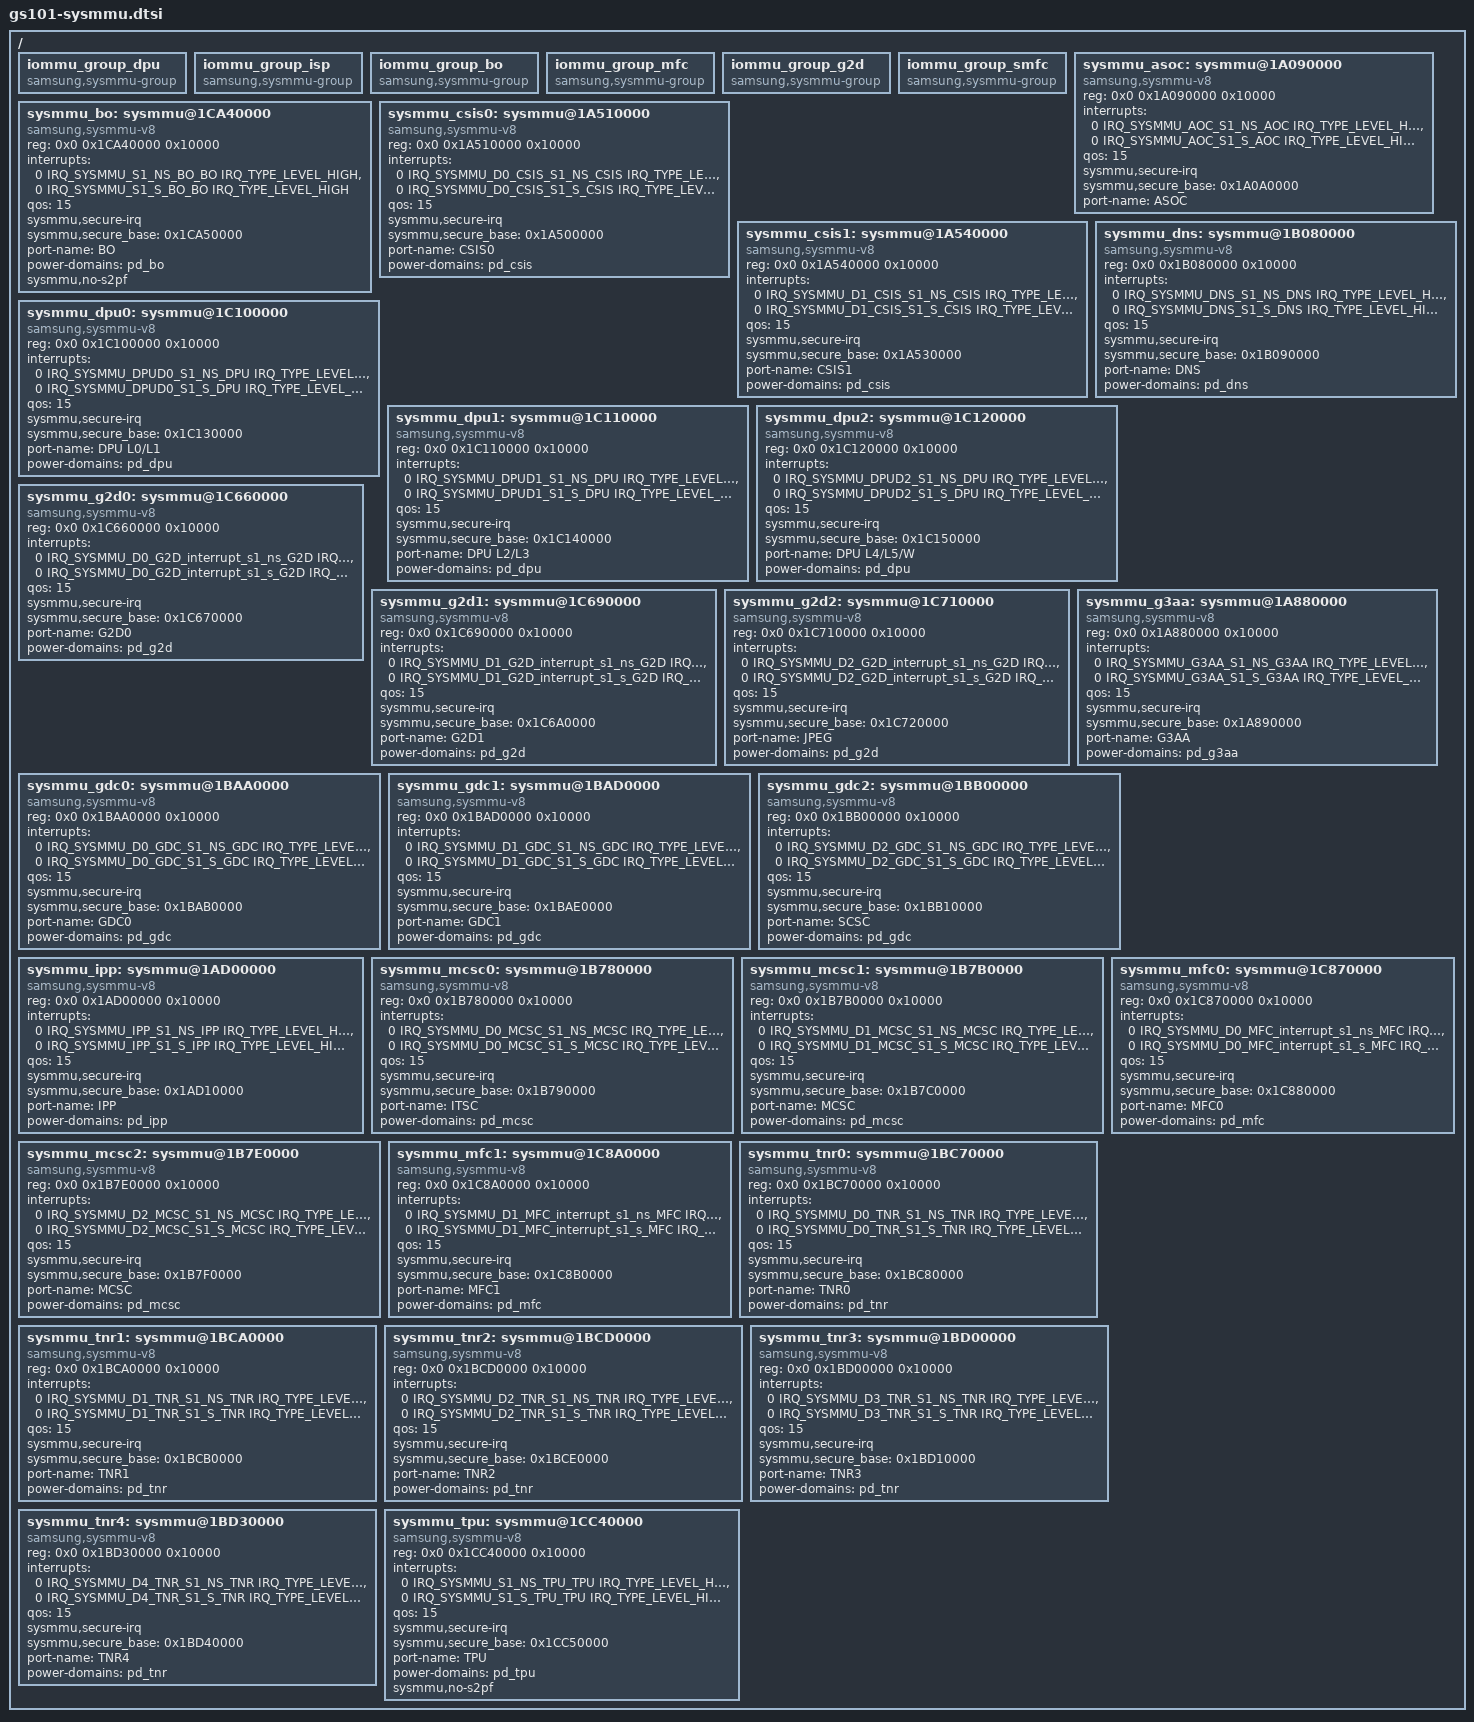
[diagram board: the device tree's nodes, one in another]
// SPDX-License-Identifier: GPL-2.0-only
/*
 * GS101 SoC System MMU
 *
 * Copyright 2019 Google LLC
 */

#include <dt-bindings/interrupt-controller/arm-gic.h>
#include <dt-bindings/interrupt-controller/gs101.h>
#include <dt-bindings/soc/samsung,sysmmu-v8.h>

/ {
	iommu_group_dpu: iommu_group_dpu {
		compatible = "samsung,sysmmu-group";
	};

	iommu_group_isp: iommu_group_isp {
		compatible = "samsung,sysmmu-group";
	};

	iommu_group_bo: iommu_group_bo {
		compatible = "samsung,sysmmu-group";
	};

	iommu_group_mfc: iommu_group_mfc {
		compatible = "samsung,sysmmu-group";
	};

	iommu_group_g2d: iommu_group_g2d {
		compatible = "samsung,sysmmu-group";
	};

	iommu_group_smfc: iommu_group_smfc {
		compatible = "samsung,sysmmu-group";
	};

	sysmmu_asoc: sysmmu@1A090000 {
		compatible = "samsung,sysmmu-v8";
		reg = <0x0 0x1A090000 0x10000>;
		interrupts = <0 IRQ_SYSMMU_AOC_S1_NS_AOC IRQ_TYPE_LEVEL_HIGH>,
			     <0 IRQ_SYSMMU_AOC_S1_S_AOC  IRQ_TYPE_LEVEL_HIGH>;
		qos = <15>;
		sysmmu,secure-irq;
		sysmmu,secure_base = <0x1A0A0000>;
		port-name = "ASOC";
		#iommu-cells = <0>;
	};

	sysmmu_bo: sysmmu@1CA40000 {
		compatible = "samsung,sysmmu-v8";
		reg = <0x0 0x1CA40000 0x10000>;
		interrupts = <0 IRQ_SYSMMU_S1_NS_BO_BO IRQ_TYPE_LEVEL_HIGH>,
			     <0 IRQ_SYSMMU_S1_S_BO_BO  IRQ_TYPE_LEVEL_HIGH>;
		qos = <15>;
		sysmmu,secure-irq;
		sysmmu,secure_base = <0x1CA50000>;
		port-name = "BO";
		#iommu-cells = <0>;
		power-domains = <&pd_bo>;
		sysmmu,no-s2pf;
	};

	sysmmu_csis0: sysmmu@1A510000 {
		compatible = "samsung,sysmmu-v8";
		reg = <0x0 0x1A510000 0x10000>;
		interrupts = <0 IRQ_SYSMMU_D0_CSIS_S1_NS_CSIS IRQ_TYPE_LEVEL_HIGH>,
			     <0 IRQ_SYSMMU_D0_CSIS_S1_S_CSIS  IRQ_TYPE_LEVEL_HIGH>;
		qos = <15>;
		sysmmu,secure-irq;
		sysmmu,secure_base = <0x1A500000>;
		port-name = "CSIS0";
		#iommu-cells = <0>;
		power-domains = <&pd_csis>;
	};

	sysmmu_csis1: sysmmu@1A540000 {
		compatible = "samsung,sysmmu-v8";
		reg = <0x0 0x1A540000 0x10000>;
		interrupts = <0 IRQ_SYSMMU_D1_CSIS_S1_NS_CSIS IRQ_TYPE_LEVEL_HIGH>,
			     <0 IRQ_SYSMMU_D1_CSIS_S1_S_CSIS  IRQ_TYPE_LEVEL_HIGH>;
		qos = <15>;
		sysmmu,secure-irq;
		sysmmu,secure_base = <0x1A530000>;
		port-name = "CSIS1";
		#iommu-cells = <0>;
		power-domains = <&pd_csis>;
	};

	sysmmu_dns: sysmmu@1B080000 {
		compatible = "samsung,sysmmu-v8";
		reg = <0x0 0x1B080000 0x10000>;
		interrupts = <0 IRQ_SYSMMU_DNS_S1_NS_DNS IRQ_TYPE_LEVEL_HIGH>,
			     <0 IRQ_SYSMMU_DNS_S1_S_DNS  IRQ_TYPE_LEVEL_HIGH>;
		qos = <15>;
		sysmmu,secure-irq;
		sysmmu,secure_base = <0x1B090000>;
		port-name = "DNS";
		#iommu-cells = <0>;
		power-domains = <&pd_dns>;
	};

	sysmmu_dpu0: sysmmu@1C100000 {
		compatible = "samsung,sysmmu-v8";
		reg = <0x0 0x1C100000 0x10000>;
		interrupts = <0 IRQ_SYSMMU_DPUD0_S1_NS_DPU IRQ_TYPE_LEVEL_HIGH>,
			     <0 IRQ_SYSMMU_DPUD0_S1_S_DPU  IRQ_TYPE_LEVEL_HIGH>;
		qos = <15>;
		sysmmu,secure-irq;
		sysmmu,secure_base = <0x1C130000>;
		port-name = "DPU L0/L1";
		#iommu-cells = <0>;
		power-domains = <&pd_dpu>;
	};

	sysmmu_dpu1: sysmmu@1C110000 {
		compatible = "samsung,sysmmu-v8";
		reg = <0x0 0x1C110000 0x10000>;
		interrupts = <0 IRQ_SYSMMU_DPUD1_S1_NS_DPU IRQ_TYPE_LEVEL_HIGH>,
			     <0 IRQ_SYSMMU_DPUD1_S1_S_DPU  IRQ_TYPE_LEVEL_HIGH>;
		qos = <15>;
		sysmmu,secure-irq;
		sysmmu,secure_base = <0x1C140000>;
		port-name = "DPU L2/L3";
		#iommu-cells = <0>;
		power-domains = <&pd_dpu>;
	};

	sysmmu_dpu2: sysmmu@1C120000 {
		compatible = "samsung,sysmmu-v8";
		reg = <0x0 0x1C120000 0x10000>;
		interrupts = <0 IRQ_SYSMMU_DPUD2_S1_NS_DPU IRQ_TYPE_LEVEL_HIGH>,
			     <0 IRQ_SYSMMU_DPUD2_S1_S_DPU  IRQ_TYPE_LEVEL_HIGH>;
		qos = <15>;
		sysmmu,secure-irq;
		sysmmu,secure_base = <0x1C150000>;
		port-name = "DPU L4/L5/W";
		#iommu-cells = <0>;
		power-domains = <&pd_dpu>;
	};

	sysmmu_g2d0: sysmmu@1C660000 {
		compatible = "samsung,sysmmu-v8";
		reg = <0x0 0x1C660000 0x10000>;
		interrupts = <0 IRQ_SYSMMU_D0_G2D_interrupt_s1_ns_G2D IRQ_TYPE_LEVEL_HIGH>,
			     <0 IRQ_SYSMMU_D0_G2D_interrupt_s1_s_G2D  IRQ_TYPE_LEVEL_HIGH>;
		qos = <15>;
		sysmmu,secure-irq;
		sysmmu,secure_base = <0x1C670000>;
		port-name = "G2D0";
		#iommu-cells = <0>;
		power-domains = <&pd_g2d>;
	};

	sysmmu_g2d1: sysmmu@1C690000 {
		compatible = "samsung,sysmmu-v8";
		reg = <0x0 0x1C690000 0x10000>;
		interrupts = <0 IRQ_SYSMMU_D1_G2D_interrupt_s1_ns_G2D IRQ_TYPE_LEVEL_HIGH>,
			     <0 IRQ_SYSMMU_D1_G2D_interrupt_s1_s_G2D  IRQ_TYPE_LEVEL_HIGH>;
		qos = <15>;
		sysmmu,secure-irq;
		sysmmu,secure_base = <0x1C6A0000>;
		port-name = "G2D1";
		#iommu-cells = <0>;
		power-domains = <&pd_g2d>;
	};

	sysmmu_g2d2: sysmmu@1C710000 {
		compatible = "samsung,sysmmu-v8";
		reg = <0x0 0x1C710000 0x10000>;
		interrupts = <0 IRQ_SYSMMU_D2_G2D_interrupt_s1_ns_G2D IRQ_TYPE_LEVEL_HIGH>,
			     <0 IRQ_SYSMMU_D2_G2D_interrupt_s1_s_G2D  IRQ_TYPE_LEVEL_HIGH>;
		qos = <15>;
		sysmmu,secure-irq;
		sysmmu,secure_base = <0x1C720000>;
		port-name = "JPEG";
		#iommu-cells = <0>;
		power-domains = <&pd_g2d>;
	};

	sysmmu_g3aa: sysmmu@1A880000 {
		compatible = "samsung,sysmmu-v8";
		reg = <0x0 0x1A880000 0x10000>;
		interrupts = <0 IRQ_SYSMMU_G3AA_S1_NS_G3AA IRQ_TYPE_LEVEL_HIGH>,
			     <0 IRQ_SYSMMU_G3AA_S1_S_G3AA  IRQ_TYPE_LEVEL_HIGH>;
		qos = <15>;
		sysmmu,secure-irq;
		sysmmu,secure_base = <0x1A890000>;
		port-name = "G3AA";
		#iommu-cells = <0>;
		power-domains = <&pd_g3aa>;
	};

	sysmmu_gdc0: sysmmu@1BAA0000 {
		compatible = "samsung,sysmmu-v8";
		reg = <0x0 0x1BAA0000 0x10000>;
		interrupts = <0 IRQ_SYSMMU_D0_GDC_S1_NS_GDC IRQ_TYPE_LEVEL_HIGH>,
			     <0 IRQ_SYSMMU_D0_GDC_S1_S_GDC  IRQ_TYPE_LEVEL_HIGH>;
		qos = <15>;
		sysmmu,secure-irq;
		sysmmu,secure_base = <0x1BAB0000>;
		port-name = "GDC0";
		#iommu-cells = <0>;
		power-domains = <&pd_gdc>;
	};

	sysmmu_gdc1: sysmmu@1BAD0000{
		compatible = "samsung,sysmmu-v8";
		reg = <0x0 0x1BAD0000 0x10000>;
		interrupts = <0 IRQ_SYSMMU_D1_GDC_S1_NS_GDC IRQ_TYPE_LEVEL_HIGH>,
			     <0 IRQ_SYSMMU_D1_GDC_S1_S_GDC  IRQ_TYPE_LEVEL_HIGH>;
		qos = <15>;
		sysmmu,secure-irq;
		sysmmu,secure_base = <0x1BAE0000>;
		port-name = "GDC1";
		#iommu-cells = <0>;
		power-domains = <&pd_gdc>;
	};

	sysmmu_gdc2: sysmmu@1BB00000 {
		compatible = "samsung,sysmmu-v8";
		reg = <0x0 0x1BB00000 0x10000>;
		interrupts = <0 IRQ_SYSMMU_D2_GDC_S1_NS_GDC IRQ_TYPE_LEVEL_HIGH>,
			     <0 IRQ_SYSMMU_D2_GDC_S1_S_GDC  IRQ_TYPE_LEVEL_HIGH>;
		qos = <15>;
		sysmmu,secure-irq;
		sysmmu,secure_base = <0x1BB10000>;
		port-name = "SCSC";
		#iommu-cells = <0>;
		power-domains = <&pd_gdc>;
	};

#if 0
	/*
	 * When GSA is in power collapse SysMMU block below is not accessible.
	 * Linux kernel driver need to coordinate access to this block with GSA
	 * if this block needs to be programmed, although, currently, there is
	 * no usecase that would require this. Disable it for now.
	 */
	sysmmu_gsa: sysmmu@17C40000 {
		compatible = "samsung,sysmmu-v8";
		reg = <0x0 0x17C40000 0x10000>;
		interrupts = <0 SYSMMU_NS__INTERRUPT_GSA IRQ_TYPE_LEVEL_HIGH>,
			     <0 SYSMMU_S__INTERRUPT_GSA  IRQ_TYPE_LEVEL_HIGH>;
		qos = <15>;
		sysmmu,secure-irq;
		sysmmu,secure_base = <0x17C50000>;
		port-name = "GSA";
		#iommu-cells = <0>;
	};
#endif

	sysmmu_ipp: sysmmu@1AD00000 {
		compatible = "samsung,sysmmu-v8";
		reg = <0x0 0x1AD00000 0x10000>;
		interrupts = <0 IRQ_SYSMMU_IPP_S1_NS_IPP IRQ_TYPE_LEVEL_HIGH>,
			     <0 IRQ_SYSMMU_IPP_S1_S_IPP  IRQ_TYPE_LEVEL_HIGH>;
		qos = <15>;
		sysmmu,secure-irq;
		sysmmu,secure_base = <0x1AD10000>;
		port-name = "IPP";
		#iommu-cells = <0>;
		power-domains = <&pd_ipp>;
	};

	sysmmu_mcsc0: sysmmu@1B780000 {
		compatible = "samsung,sysmmu-v8";
		reg = <0x0 0x1B780000 0x10000>;
		interrupts = <0 IRQ_SYSMMU_D0_MCSC_S1_NS_MCSC IRQ_TYPE_LEVEL_HIGH>,
			     <0 IRQ_SYSMMU_D0_MCSC_S1_S_MCSC  IRQ_TYPE_LEVEL_HIGH>;
		qos = <15>;
		sysmmu,secure-irq;
		sysmmu,secure_base = <0x1B790000>;
		port-name = "ITSC";
		#iommu-cells = <0>;
		power-domains = <&pd_mcsc>;
	};

	sysmmu_mcsc1: sysmmu@1B7B0000 {
		compatible = "samsung,sysmmu-v8";
		reg = <0x0 0x1B7B0000 0x10000>;
		interrupts = <0 IRQ_SYSMMU_D1_MCSC_S1_NS_MCSC IRQ_TYPE_LEVEL_HIGH>,
			     <0 IRQ_SYSMMU_D1_MCSC_S1_S_MCSC  IRQ_TYPE_LEVEL_HIGH>;
		qos = <15>;
		sysmmu,secure-irq;
		sysmmu,secure_base = <0x1B7C0000>;
		port-name = "MCSC";
		#iommu-cells = <0>;
		power-domains = <&pd_mcsc>;
	};

	sysmmu_mcsc2: sysmmu@1B7E0000 {
		compatible = "samsung,sysmmu-v8";
		reg = <0x0 0x1B7E0000 0x10000>;
		interrupts = <0 IRQ_SYSMMU_D2_MCSC_S1_NS_MCSC IRQ_TYPE_LEVEL_HIGH>,
			     <0 IRQ_SYSMMU_D2_MCSC_S1_S_MCSC  IRQ_TYPE_LEVEL_HIGH>;
		qos = <15>;
		sysmmu,secure-irq;
		sysmmu,secure_base = <0x1B7F0000>;
		port-name = "MCSC";
		#iommu-cells = <0>;
		power-domains = <&pd_mcsc>;
	};

	sysmmu_mfc0: sysmmu@1C870000 {
		compatible = "samsung,sysmmu-v8";
		reg = <0x0 0x1C870000 0x10000>;
		interrupts = <0 IRQ_SYSMMU_D0_MFC_interrupt_s1_ns_MFC IRQ_TYPE_LEVEL_HIGH>,
			     <0 IRQ_SYSMMU_D0_MFC_interrupt_s1_s_MFC  IRQ_TYPE_LEVEL_HIGH>;
		qos = <15>;
		sysmmu,secure-irq;
		sysmmu,secure_base = <0x1C880000>;
		port-name = "MFC0";
		#iommu-cells = <0>;
		power-domains = <&pd_mfc>;
	};

	sysmmu_mfc1: sysmmu@1C8A0000 {
		compatible = "samsung,sysmmu-v8";
		reg = <0x0 0x1C8A0000 0x10000>;
		interrupts = <0 IRQ_SYSMMU_D1_MFC_interrupt_s1_ns_MFC IRQ_TYPE_LEVEL_HIGH>,
			     <0 IRQ_SYSMMU_D1_MFC_interrupt_s1_s_MFC  IRQ_TYPE_LEVEL_HIGH>;
		qos = <15>;
		sysmmu,secure-irq;
		sysmmu,secure_base = <0x1C8B0000>;
		port-name = "MFC1";
		#iommu-cells = <0>;
		power-domains = <&pd_mfc>;
	};

	sysmmu_tnr0: sysmmu@1BC70000 {
		compatible = "samsung,sysmmu-v8";
		reg = <0x0 0x1BC70000 0x10000>;
		interrupts = <0 IRQ_SYSMMU_D0_TNR_S1_NS_TNR IRQ_TYPE_LEVEL_HIGH>,
			     <0 IRQ_SYSMMU_D0_TNR_S1_S_TNR  IRQ_TYPE_LEVEL_HIGH>;
		qos = <15>;
		sysmmu,secure-irq;
		sysmmu,secure_base = <0x1BC80000>;
		port-name = "TNR0";
		#iommu-cells = <0>;
		power-domains = <&pd_tnr>;
	};

	sysmmu_tnr1: sysmmu@1BCA0000 {
		compatible = "samsung,sysmmu-v8";
		reg = <0x0 0x1BCA0000 0x10000>;
		interrupts = <0 IRQ_SYSMMU_D1_TNR_S1_NS_TNR IRQ_TYPE_LEVEL_HIGH>,
			     <0 IRQ_SYSMMU_D1_TNR_S1_S_TNR  IRQ_TYPE_LEVEL_HIGH>;
		qos = <15>;
		sysmmu,secure-irq;
		sysmmu,secure_base = <0x1BCB0000>;
		port-name = "TNR1";
		#iommu-cells = <0>;
		power-domains = <&pd_tnr>;
	};

	sysmmu_tnr2: sysmmu@1BCD0000 {
		compatible = "samsung,sysmmu-v8";
		reg = <0x0 0x1BCD0000 0x10000>;
		interrupts = <0 IRQ_SYSMMU_D2_TNR_S1_NS_TNR IRQ_TYPE_LEVEL_HIGH>,
			     <0 IRQ_SYSMMU_D2_TNR_S1_S_TNR  IRQ_TYPE_LEVEL_HIGH>;
		qos = <15>;
		sysmmu,secure-irq;
		sysmmu,secure_base = <0x1BCE0000>;
		port-name = "TNR2";
		#iommu-cells = <0>;
		power-domains = <&pd_tnr>;
	};

	sysmmu_tnr3: sysmmu@1BD00000 {
		compatible = "samsung,sysmmu-v8";
		reg = <0x0 0x1BD00000 0x10000>;
		interrupts = <0 IRQ_SYSMMU_D3_TNR_S1_NS_TNR IRQ_TYPE_LEVEL_HIGH>,
			     <0 IRQ_SYSMMU_D3_TNR_S1_S_TNR  IRQ_TYPE_LEVEL_HIGH>;
		qos = <15>;
		sysmmu,secure-irq;
		sysmmu,secure_base = <0x1BD10000>;
		port-name = "TNR3";
		#iommu-cells = <0>;
		power-domains = <&pd_tnr>;
	};

	sysmmu_tnr4: sysmmu@1BD30000 {
		compatible = "samsung,sysmmu-v8";
		reg = <0x0 0x1BD30000 0x10000>;
		interrupts = <0 IRQ_SYSMMU_D4_TNR_S1_NS_TNR IRQ_TYPE_LEVEL_HIGH>,
			     <0 IRQ_SYSMMU_D4_TNR_S1_S_TNR  IRQ_TYPE_LEVEL_HIGH>;
		qos = <15>;
		sysmmu,secure-irq;
		sysmmu,secure_base = <0x1BD40000>;
		port-name = "TNR4";
		#iommu-cells = <0>;
		power-domains = <&pd_tnr>;
	};

	sysmmu_tpu: sysmmu@1CC40000 {
		compatible = "samsung,sysmmu-v8";
		reg = <0x0 0x1CC40000 0x10000>;
		interrupts = <0 IRQ_SYSMMU_S1_NS_TPU_TPU IRQ_TYPE_LEVEL_HIGH>,
			     <0 IRQ_SYSMMU_S1_S_TPU_TPU  IRQ_TYPE_LEVEL_HIGH>;
		qos = <15>;
		sysmmu,secure-irq;
		sysmmu,secure_base = <0x1CC50000>;
		port-name = "TPU";
		#iommu-cells = <0>;
		power-domains = <&pd_tpu>;
		sysmmu,no-s2pf;
	};
};
